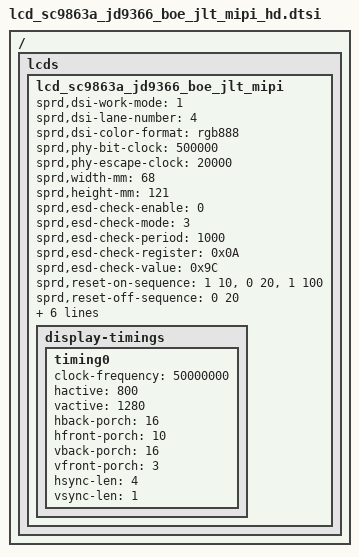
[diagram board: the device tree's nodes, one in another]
/ { lcds {
	lcd_sc9863a_jd9366_boe_jlt_mipi: lcd_sc9863a_jd9366_boe_jlt_mipi {

		sprd,dsi-work-mode = <1>;
		sprd,dsi-lane-number = <4>;
		sprd,dsi-color-format = "rgb888";

		sprd,phy-bit-clock = <500000>;
		sprd,phy-escape-clock = <20000>;

		sprd,width-mm = <68>;
		sprd,height-mm = <121>;

		sprd,esd-check-enable = <0>;
		sprd,esd-check-mode = <3>;
		sprd,esd-check-period = <1000>;
		sprd,esd-check-register = <0x0A>;
		sprd,esd-check-value = <0x9C>;

		sprd,reset-on-sequence = <1 10>, <0 20>, <1 100>;
		sprd,reset-off-sequence = <0 20>;

		sprd,initial-command = [
		
			23 00 00 02 E0 00 
			//--- PASSWORD  ----//
			 23 00 00 02 E1 93 
			 23 00 00 02 E2 65 
			 23 00 00 02 E3 F8 
			 23 00 00 02 80 03 

				//--- Page4  ----//
			  23 00 00 02 E0 04 
			  23 00 00 02 2D 03 

				//--- Page1  ----//
			  23 00 00 02 E0 01 
			   // {LCM_SEND(2) {  4A 35 	

				//Set VCOM
			  23 00 00 02 00 00 
			  23 00 00 02 01 A9 	//VCOM A8 AE AD
				//Set VCOM_Reverse
			  23 00 00 02 03 00 
			  23 00 00 02 04 A8 	

				//Set Gamma Power   VGMP  VGMN  VGSP  VGSN
			  23 00 00 02 17 00 
			  23 00 00 02 18 B1 
			  23 00 00 02 19 01 
			  23 00 00 02 1A 00 
			  23 00 00 02 1B B1   //VGMN=0
			  23 00 00 02 1C 01 

				//Set Gate Power
			  23 00 00 02 1F 3E      //VGH_R  = 15V                       
			  23 00 00 02 20 2D      //VGL_R  = -12V                      
			  23 00 00 02 21 2D      //VGL_R2 = -12V                      
			  23 00 00 02 22 7E      //PA[6]=0   PA[5]=0   PA[4]=0   PA[0]=0 

				//SETPANEL
			  23 00 00 02 37 19 	//SS=1  BGR=1

				//SET RGBCYC
			  23 00 00 02 38 05 	//JDT=101 zigzag inversion
			  23 00 00 02 39 00 	//RGB_N_EQ1   modify 20140806
			  23 00 00 02 3A 01 	//RGB_N_EQ2   modify 20140806
			  23 00 00 02 3C 78 	//SET EQ3 for TE_H
			  23 00 00 02 3D FF 	//SET CHGEN_OFF   modify 20140827 
			  23 00 00 02 3E FF 	//SET CHGEN_OFF   modify 20140827 
			  23 00 00 02 3F FF 	//SET CHGEN_OFF2   modify 20140827
		//	  23 00 00 02 3E 80 	//SET CHGEN_OFF   modify 20140806 
		//	  23 00 00 02 3F 80 	//SET CHGEN_OFF2   modify 20140806

				//Set TCON
			  23 00 00 02 40 06 	//RSO=800 RGB
			  23 00 00 02 41 A0 	//LN=640->1280 line

			  23 00 00 02 43 08 
			  23 00 00 02 44 09 
			  23 00 00 02 45 28 

				//--- power voltage  ----//
			  23 00 00 02 55 0F 	//DCDCM=1111
		//	  23 00 00 02 56 01 
			  23 00 00 02 57 89 	//VGH_RT=100   Charge pump Ratio:3*AVDD-VCL
			  23 00 00 02 58 0A 
			  23 00 00 02 59 0A 	//VCL = -2.5V
			  23 00 00 02 5A 28 	//VGH = 15V
			  23 00 00 02 5B 19 	//VGL = -12V

				//--- Gamma  ----//
			  23 00 00 02 5D 7C  // 
			  23 00 00 02 5E 66  //
			  23 00 00 02 5F 56  //
			  23 00 00 02 60 49  //
			  23 00 00 02 61 44  //
			  23 00 00 02 62 34  //
			  23 00 00 02 63 37  //
			  23 00 00 02 64 1F  //
			  23 00 00 02 65 36  //
			  23 00 00 02 66 33  //
			  23 00 00 02 67 32  //
			  23 00 00 02 68 4F  //
			  23 00 00 02 69 3D  //
			  23 00 00 02 6A 43  //
			  23 00 00 02 6B 35  //
			  23 00 00 02 6C 30  //
			  23 00 00 02 6D 24  //
			  23 00 00 02 6E 13  //
			  23 00 00 02 6F 00  //
			  23 00 00 02 70 7C  //
			  23 00 00 02 71 66  //
			  23 00 00 02 72 56  //
			  23 00 00 02 73 49  //
			  23 00 00 02 74 44  //
			  23 00 00 02 75 34  //
			  23 00 00 02 76 37  //
			  23 00 00 02 77 1F  //
			  23 00 00 02 78 36  //
			  23 00 00 02 79 33  //
			  23 00 00 02 7A 32  //
			  23 00 00 02 7B 4F  //
			  23 00 00 02 7C 3D  //
			  23 00 00 02 7D 43  //
			  23 00 00 02 7E 35  //
			  23 00 00 02 7F 30  //
			  23 00 00 02 80 24  //
			  23 00 00 02 81 13  //
			  23 00 00 02 82 00  //

				//Page2   for GIP
			  23 00 00 02 E0 02 

				//GIP_L Pin mapping
			  23 00 00 02 00 05 
			  23 00 00 02 01 05    
			  23 00 00 02 02 04  
			  23 00 00 02 03 04  
			  23 00 00 02 04 07  
			  23 00 00 02 05 07  
			  23 00 00 02 06 06  
			  23 00 00 02 07 06  
			  23 00 00 02 08 00  
			  23 00 00 02 09 1F  
			  23 00 00 02 0A 1F  
			  23 00 00 02 0B 1F  
			  23 00 00 02 0C 1F  
			  23 00 00 02 0D 1F  
			  23 00 00 02 0E 1F  
			  23 00 00 02 0F 01  
			  23 00 00 02 10 1F  
			  23 00 00 02 11 1F  
			  23 00 00 02 12 1F  
			  23 00 00 02 13 1F  
			  23 00 00 02 14 1F  
			  23 00 00 02 15 1F  

				//GIP_R Pin mapping
			  23 00 00 02 16 05 
			  23 00 00 02 17 05    
			  23 00 00 02 18 04  
			  23 00 00 02 19 04  
			  23 00 00 02 1A 07  
			  23 00 00 02 1B 07  
			  23 00 00 02 1C 06  
			  23 00 00 02 1D 06  
			  23 00 00 02 1E 00  
			  23 00 00 02 1F 1F  
			  23 00 00 02 20 1F  
			  23 00 00 02 21 1F  
			  23 00 00 02 22 1F  
			  23 00 00 02 23 1F  
			  23 00 00 02 24 1F  
			  23 00 00 02 25 01  
			  23 00 00 02 26 1F  
			  23 00 00 02 27 1F  
			  23 00 00 02 28 1F  
			  23 00 00 02 29 1F  
			  23 00 00 02 2A 1F  
			  23 00 00 02 2B 1F  

				//GIP Timing  
			  23 00 00 02 58 10  
			  23 00 00 02 59 00  
			  23 00 00 02 5A 00  
			  23 00 00 02 5B 10  
			  23 00 00 02 5C 0E  
			  23 00 00 02 5D 20  
			  23 00 00 02 5E 00  
			  23 00 00 02 5F 00  
			  23 00 00 02 60 00  
			  23 00 00 02 61 00  
			  23 00 00 02 62 00  
			  23 00 00 02 63 03  //STV_ON
			  23 00 00 02 64 70  //STV_OFF
			  23 00 00 02 65 00  
			  23 00 00 02 66 00  
			  23 00 00 02 67 31  
			  23 00 00 02 68 10  
			  23 00 00 02 69 06  //CKV_ON
			  23 00 00 02 6A 70  //CKV_OFF
			  23 00 00 02 6B 00  
			  23 00 00 02 6C 00  
			  23 00 00 02 6D 04  
			  23 00 00 02 6E 04  
			  23 00 00 02 6F 88  
			  23 00 00 02 70 00  
			  23 00 00 02 71 00  
			  23 00 00 02 72 06  
			  23 00 00 02 73 7B  
			  23 00 00 02 74 00  
			  23 00 00 02 75 87  
			  23 00 00 02 76 00  
			  23 00 00 02 77 5D  
			  23 00 00 02 78 17  
			  23 00 00 02 79 1F  
			  23 00 00 02 7A 00  
			  23 00 00 02 7B 00  
			  23 00 00 02 7C 00  
			  23 00 00 02 7D 03  
			  23 00 00 02 7E 7B  

				//Page3
			  23 00 00 02 E0 03 
			  23 00 00 02 98 3E 	//From 2E to 3E   LED_ON

				//Page4
			  23 00 00 02 E0 04   //ESD protect
			  23 00 00 02 09 10 
			  23 00 00 02 2B 2B 	
			  23 00 00 02 2D 03 	
			  23 00 00 02 2E 44 

				//Page0
			  23 00 00 02 E0 00  //Watch dog
			  23 00 00 02 E6 02 
			  23 00 00 02 E7 06 
			 13 78 00 01 11
			 13 64 00 01 29
			];
		sprd,sleep-in-command = [
			13 0A 00 01 28
			13 78 00 01 10
			];
		sprd,sleep-out-command = [
			13 78 00 01 11
			13 64 00 01 29
			];

		display-timings {
			timing0 {
			clock-frequency = <50000000>;
			hactive = <800>;
			vactive = <1280>;
			hback-porch = <16>;
			hfront-porch = <10>;
			vback-porch = <16>;
			vfront-porch = <3>;
			hsync-len = <4>;
				vsync-len = <1>;
			};
		};
	};
};};

